AUTOSAR XML (schema 4-2-2)
package /Rover_NoSF_v1_pkg/Rover_NoSF_v1_swc
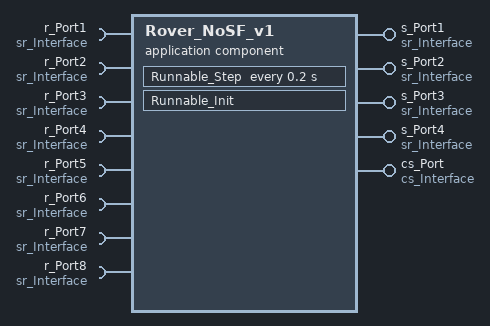
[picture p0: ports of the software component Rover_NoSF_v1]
  application sw component type Rover_NoSF_v1
    8 x require port, all with required-interface=sr_Interface:
      r_Port1: nonqueued-receiver-com-spec{data-element=Sensor_BL, alive-timeout=60, init-value=constant-reference={short-label=DefaultInitValue_Double, constant=DefaultInitValue_Double}}
      r_Port2: nonqueued-receiver-com-spec{data-element=Sensor_BC, alive-timeout=60, init-value=constant-reference={short-label=DefaultInitValue_Double, constant=DefaultInitValue_Double}}
      r_Port3: nonqueued-receiver-com-spec{data-element=Sensor_BR, alive-timeout=60, init-value=constant-reference={short-label=DefaultInitValue_Double, constant=DefaultInitValue_Double}}
      r_Port4: nonqueued-receiver-com-spec{data-element=Sensor_FL, alive-timeout=60, init-value=constant-reference={short-label=DefaultInitValue_Double, constant=DefaultInitValue_Double}}
      r_Port5: nonqueued-receiver-com-spec{data-element=Sensor_FC, alive-timeout=60, init-value=constant-reference={short-label=DefaultInitValue_Double, constant=DefaultInitValue_Double}}
      r_Port6: nonqueued-receiver-com-spec{data-element=Sensor_FR, alive-timeout=60, init-value=constant-reference={short-label=DefaultInitValue_Double, constant=DefaultInitValue_Double}}
      r_Port7: nonqueued-receiver-com-spec{data-element=Drive_Direct, alive-timeout=60, init-value=constant-reference={short-label=DefaultInitValue_Double, constant=DefaultInitValue_Double}}
      r_Port8: nonqueued-receiver-com-spec{data-element=Turn_Direct, alive-timeout=60, init-value=constant-reference={short-label=DefaultInitValue_Double, constant=DefaultInitValue_Double}}
    5 x provide port:
      s_Port1: nonqueued-sender-com-spec{data-element=TR_Right, init-value=constant-reference={short-label=DefaultInitValue_Double, constant=DefaultInitValue_Double}}, provided-interface=sr_Interface
      s_Port2: nonqueued-sender-com-spec{data-element=TR_Left, init-value=constant-reference={short-label=DefaultInitValue_Double, constant=DefaultInitValue_Double}}, provided-interface=sr_Interface
      s_Port3: nonqueued-sender-com-spec{data-element=Lim_Speed_B, init-value=constant-reference={short-label=DefaultInitValue_Double, constant=DefaultInitValue_Double}}, provided-interface=sr_Interface
      s_Port4: nonqueued-sender-com-spec{data-element=Lim_Speed_F, init-value=constant-reference={short-label=DefaultInitValue_Double, constant=DefaultInitValue_Double}}, provided-interface=sr_Interface
      cs_Port: provided-interface=cs_Interface
    behavior Rover_NoSF_v1: handle-termination-and-restart=NO-SUPPORT, supports-multiple-instantiation=true
      timing event Event_Runnable_Step: start-on-event=Runnable_Step, period=0.2
      per instance memory ATRover_DW: type=DW_ATRover_T_type, type-definition=DW_ATRover_T
      runnable Runnable_Init
      runnable Runnable_Step
        data-read-access:
          8 x access:
            IN_r_Port7_Drive_Direct: accessed-variable=r_Port7.Drive_Direct
            IN_r_Port2_Sensor_BC: accessed-variable=r_Port2.Sensor_BC
            IN_r_Port1_Sensor_BL: accessed-variable=r_Port1.Sensor_BL
            IN_r_Port3_Sensor_BR: accessed-variable=r_Port3.Sensor_BR
            IN_r_Port5_Sensor_FC: accessed-variable=r_Port5.Sensor_FC
            IN_r_Port4_Sensor_FL: accessed-variable=r_Port4.Sensor_FL
            IN_r_Port6_Sensor_FR: accessed-variable=r_Port6.Sensor_FR
            IN_r_Port8_Turn_Direct: accessed-variable=r_Port8.Turn_Direct
        data-write-access:
          4 x access:
            OUT_s_Port1_TR_Right: accessed-variable=s_Port1.TR_Right
            OUT_s_Port2_TR_Left: accessed-variable=s_Port2.TR_Left
            OUT_s_Port3_Lim_Speed_B: accessed-variable=s_Port3.Lim_Speed_B
            OUT_s_Port4_Lim_Speed_F: accessed-variable=s_Port4.Lim_Speed_F
